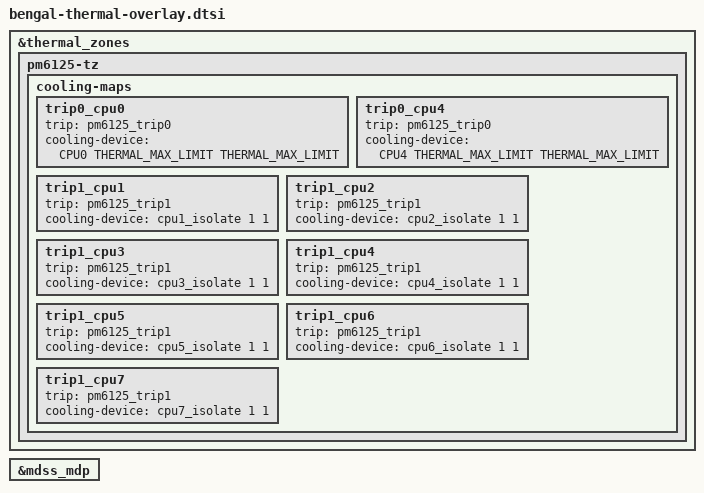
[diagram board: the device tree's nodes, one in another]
#include <dt-bindings/thermal/thermal.h>

&thermal_zones {
	pm6125-tz {
		cooling-maps {
			trip0_cpu0 {
				trip = <&pm6125_trip0>;
				cooling-device =
					<&CPU0 THERMAL_MAX_LIMIT
						THERMAL_MAX_LIMIT>;
			};

			trip0_cpu4 {
				trip = <&pm6125_trip0>;
				cooling-device =
					<&CPU4 THERMAL_MAX_LIMIT
						THERMAL_MAX_LIMIT>;
			};

			trip1_cpu1 {
				trip = <&pm6125_trip1>;
				cooling-device = <&cpu1_isolate 1 1>;
			};

			trip1_cpu2 {
				trip = <&pm6125_trip1>;
				cooling-device = <&cpu2_isolate 1 1>;
			};

			trip1_cpu3 {
				trip = <&pm6125_trip1>;
				cooling-device = <&cpu3_isolate 1 1>;
			};

			trip1_cpu4 {
				trip = <&pm6125_trip1>;
				cooling-device = <&cpu4_isolate 1 1>;
			};

			trip1_cpu5 {
				trip = <&pm6125_trip1>;
				cooling-device = <&cpu5_isolate 1 1>;
			};

			trip1_cpu6 {
				trip = <&pm6125_trip1>;
				cooling-device = <&cpu6_isolate 1 1>;
			};

			trip1_cpu7 {
				trip = <&pm6125_trip1>;
				cooling-device = <&cpu7_isolate 1 1>;
			};
		};
	};
};

&mdss_mdp {
	#cooling-cells = <2>;
};
